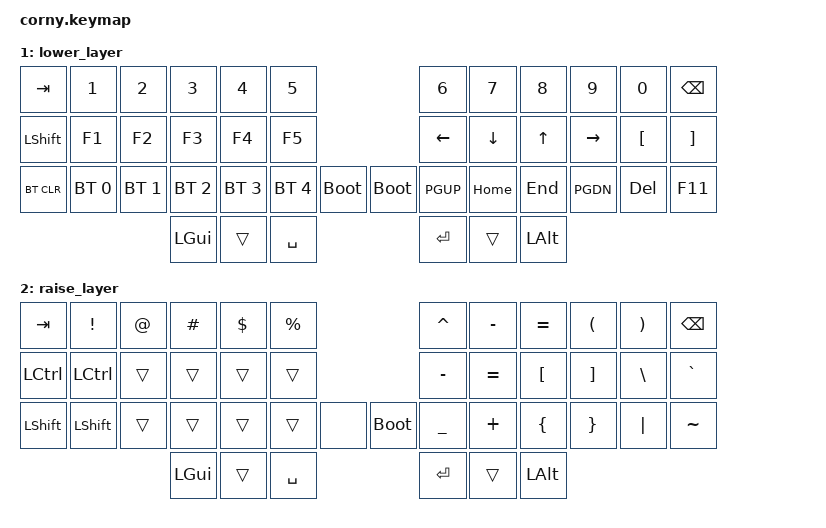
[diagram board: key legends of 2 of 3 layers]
#include <behaviors.dtsi>
#include <dt-bindings/zmk/keys.h>
#include <dt-bindings/zmk/bt.h>

// Home row mods macro
#define HRML(k1,k2,k3,k4) &ht LGUI k1  &ht LALT k2  &ht LCTRL k3 &ht LSHIFT k4
#define HRMR(k1,k2,k3,k4) &ht RSHIFT k1  &ht RCTRL k2  &ht LALT k3 &ht RGUI k4

/ {

	combos {
	    compatible = "zmk,combos";
	    combo_studio_unlock {
		timeout-ms = <50>;
		key-positions = <0 1>;
		bindings = <&studio_unlock>;
	    };
	    combo_capslock {
		timeout-ms = <50>;
		key-positions = <16 19>;  // F key (position 16) + J key (position 19) - persistent caps
		bindings = <&caps_word_persist>;
	    };
	    combo_caps_word {
		timeout-ms = <50>;
		key-positions = <15 20>;  // D key (position 15) + K key (position 20) - normal caps_word
		bindings = <&caps_word>;
	    };
	};

	behaviors {
	  caps_word_persist: caps_word_persist {
	    compatible = "zmk,behavior-caps-word";
	    #binding-cells = <0>;
	    continue-list = <UNDERSCORE MINUS BACKSPACE DELETE SPACE>;
	  };
	  rpi: require_prior_idle {
	    compatible = "zmk,behavior-hold-tap";
	    #binding-cells = <2>;
	    flavor = "tap-preferred";
	    tapping-term-ms = <200>;
	    quick-tap-ms = <200>;
	    require-prior-idle-ms = <125>;
	    bindings = <&kp>, <&kp>;
	  };
	  ht: hold_tap {
	    label = "hold_tap";
	    compatible = "zmk,behavior-hold-tap";
	    #binding-cells = <2>;
	    flavor = "tap-preferred";
	    tapping-term-ms = <200>;
	    quick-tap-ms = <150>;
	    global-quick-tap;
	    bindings = <&kp>, <&kp>;
	  };
	};

        keymap {
                compatible = "zmk,keymap";

                default_layer {
// -------------------------------------------------------------------------------------------------
// |  TAB |  Q  |  W  |  E  |  R  |  T  |                    |  Y  |  U   |  I  |  O  |  P  | BKSP |
// | CTRL |  A  |  S  |  D  |  F  |  G  |                    |  H  |  J   |  K  |  L  |  ;  |  '   |
// | SHFT |  Z  |  X  |  C  |  V  |  B  |  MUTE  |  |  MUTE  |  N  |  M   |  ,  |  .  |  /  | ESC  |
//                    | ESC | TAB/L1 | SPC |                    | ENT | BKSP/L1  | ESC |
                        bindings = <
   &kp TAB   &kp Q &kp W &kp E &kp R &kp T                   &kp Y &kp U  &kp I     &kp O   &kp P    &kp BSPC
   &kp LCTRL HRML(A,S,D,F)           &kp G                   &kp H HRMR(J,K,L, SEMI)                 &kp SQT
   &kp LSHFT &kp Z &kp X &kp C &kp V &kp B &kp C_MUTE  &kp C_MUTE &kp N &kp M  &kp COMMA &kp DOT &kp FSLH &kp ESC
                  &kp ESC &lt 1 TAB &lt 2 SPACE                   &lt 2 RET &lt 1 BKSP &kp ESC
                        >;

                        sensor-bindings = <&inc_dec_kp C_VOL_UP C_VOL_DN &inc_dec_kp C_VOL_UP C_VOL_DN>;
                };
                lower_layer {
// ------------------------------------------------------------------------------------------------
// |  TAB |  1  |  2  |  3  |  4  |  5  |                    |  6  | 7   | 8   | 9   |  0  | BKSP |
// | SHFT | F1  | F2  | F3  | F4  | F5  |                    | LFT | DWN | UP  | RGT | [/} | ]/}  |
// | BTCLR| BT1 | BT2 | BT3 | BT4 | BT5 |  boot  |  |  boot  | PGUP| HOME| END | PGDN| F10 |  F11 |
//                    | GUI |     | SPC |                    | ENT |     | ALT |
                        bindings = <
   &kp TAB    &kp N1       &kp N2       &kp N3       &kp N4       &kp N5                           &kp N6   &kp N7      &kp N8    &kp N9    &kp N0  &kp BSPC
   &kp LSHFT  &kp F1       &kp F2       &kp F3       &kp F4       &kp F5                           &kp LEFT &kp DOWN    &kp UP    &kp RIGHT &kp LBKT  &kp RBKT
   &bt BT_CLR &bt BT_SEL 0 &bt BT_SEL 1 &bt BT_SEL 2 &bt BT_SEL 3 &bt BT_SEL 4 &bootloader  &bootloader  &kp PGUP &kp HOME    &kp END   &kp PGDN  &kp DEL &kp F11
                                    &kp LGUI     &trans       &kp SPACE                            &kp RET  &trans      &kp LALT
                        >;

                        sensor-bindings = <&inc_dec_kp PG_UP PG_DN &inc_dec_kp C_VOL_UP C_VOL_DN>;
                };

                raise_layer {
// ------------------------------------------------------------------------------------------------
// |  TAB |  !  |  @  |  #  |  $  |  %  |                    |  ^  | -/_ | =/+ |  (  |  )  | BKSP |
// | CTRL |LCTRL|     |     |     |     |                    |  -  |  =  |  [  |  ]  |  \  |  `   |
// | SHFT |LSHFT|     |     |     |     |        |  |  boot  |  _  |  +  |  {  |  }  | "|" |  ~   |
//                    | GUI |     | SPC |                    | ENT |     | ALT |
                        bindings = <
   &kp  TAB  &kp EXCL  &kp AT &kp HASH &kp DLLR &kp PRCNT                    &kp CARET &kp MINUS &kp EQUAL &kp LPAR &kp RPAR &kp BSPC
   &kp LCTRL &kp LCTRL &trans &trans   &trans   &trans                       &kp MINUS &kp EQUAL &kp LBKT        &kp RBKT &kp BSLH &kp GRAVE
   &kp LSHFT &kp LSHFT &trans &trans   &trans   &trans    &none  &bootloader &kp UNDER &kp PLUS  &kp LBRC        &kp RBRC &kp PIPE &kp TILDE
                             &kp LGUI &trans   &kp SPACE                    &kp RET   &trans    &kp LALT
                        >;

                        sensor-bindings = <&inc_dec_kp PG_UP PG_DN &inc_dec_kp C_VOL_UP C_VOL_DN>;
                };
        };

        extra1 {
            status = "reserved";
        };

        extra2 {
            status = "reserved";
        };
};
